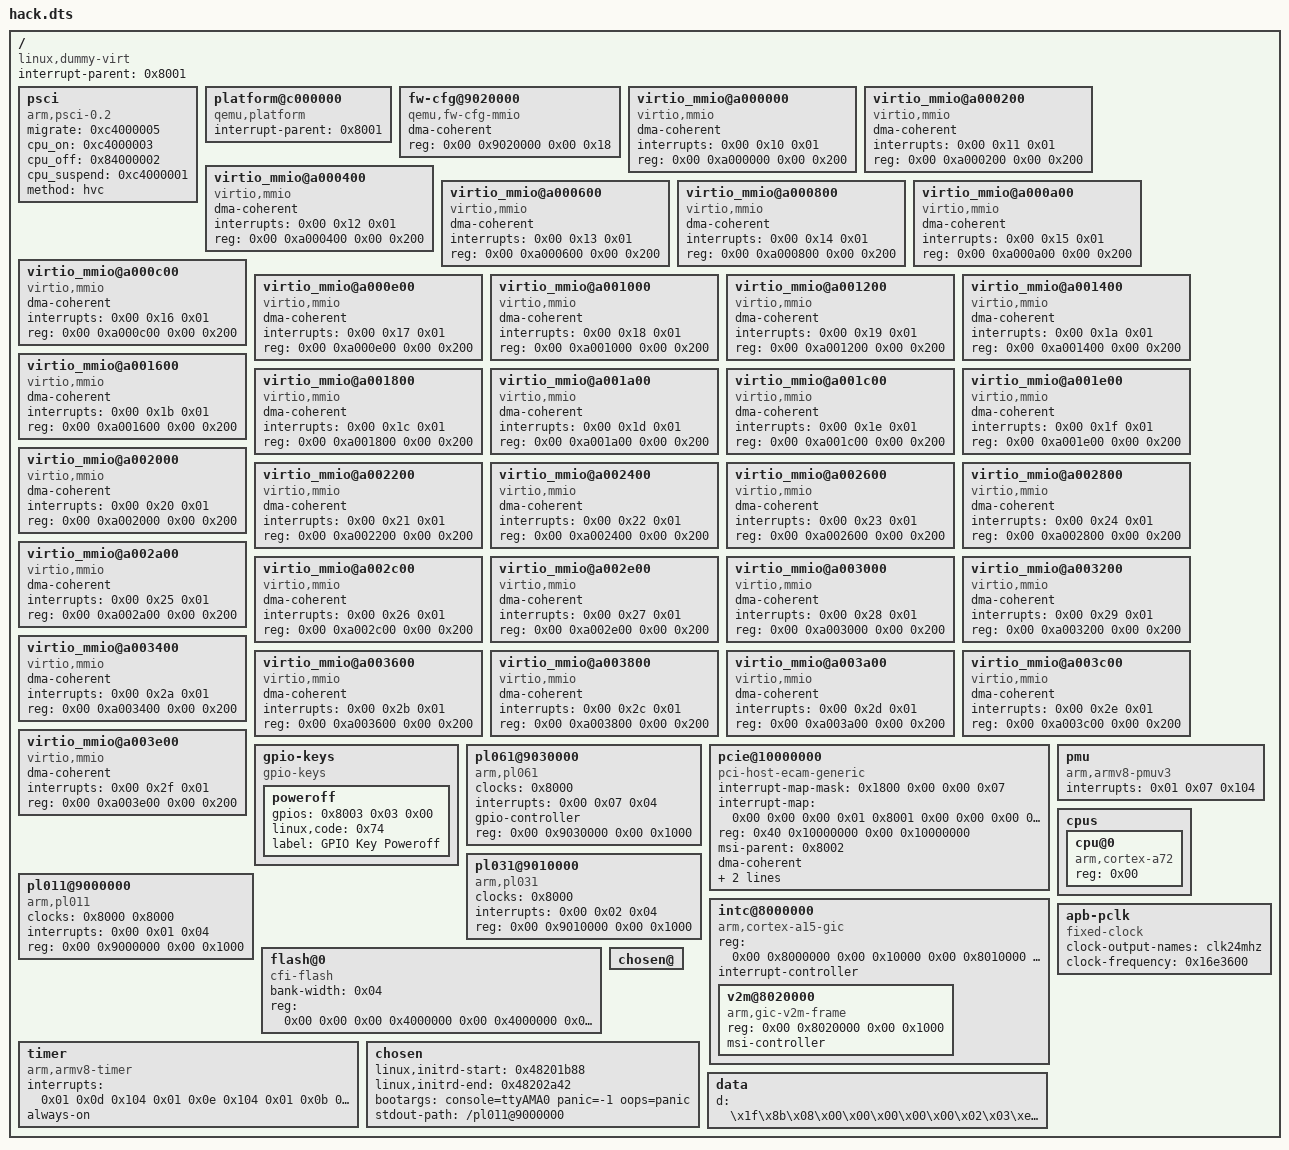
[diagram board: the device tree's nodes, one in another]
/dts-v1/;

/ {
	interrupt-parent = <0x8001>;
	#size-cells = <0x02>;
	#address-cells = <0x02>;
	compatible = "linux,dummy-virt";

	psci {
		migrate = <0xc4000005>;
		cpu_on = <0xc4000003>;
		cpu_off = <0x84000002>;
		cpu_suspend = <0xc4000001>;
		method = "hvc";
		compatible = "arm,psci-0.2\0arm,psci";
	};

	platform@c000000 {
		interrupt-parent = <0x8001>;
		ranges = <0x00 0x00 0xc000000 0x2000000>;
		#address-cells = <0x01>;
		#size-cells = <0x01>;
		compatible = "qemu,platform\0simple-bus";
	};

	fw-cfg@9020000 {
		dma-coherent;
		reg = <0x00 0x9020000 0x00 0x18>;
		compatible = "qemu,fw-cfg-mmio";
	};

	virtio_mmio@a000000 {
		dma-coherent;
		interrupts = <0x00 0x10 0x01>;
		reg = <0x00 0xa000000 0x00 0x200>;
		compatible = "virtio,mmio";
	};

	virtio_mmio@a000200 {
		dma-coherent;
		interrupts = <0x00 0x11 0x01>;
		reg = <0x00 0xa000200 0x00 0x200>;
		compatible = "virtio,mmio";
	};

	virtio_mmio@a000400 {
		dma-coherent;
		interrupts = <0x00 0x12 0x01>;
		reg = <0x00 0xa000400 0x00 0x200>;
		compatible = "virtio,mmio";
	};

	virtio_mmio@a000600 {
		dma-coherent;
		interrupts = <0x00 0x13 0x01>;
		reg = <0x00 0xa000600 0x00 0x200>;
		compatible = "virtio,mmio";
	};

	virtio_mmio@a000800 {
		dma-coherent;
		interrupts = <0x00 0x14 0x01>;
		reg = <0x00 0xa000800 0x00 0x200>;
		compatible = "virtio,mmio";
	};

	virtio_mmio@a000a00 {
		dma-coherent;
		interrupts = <0x00 0x15 0x01>;
		reg = <0x00 0xa000a00 0x00 0x200>;
		compatible = "virtio,mmio";
	};

	virtio_mmio@a000c00 {
		dma-coherent;
		interrupts = <0x00 0x16 0x01>;
		reg = <0x00 0xa000c00 0x00 0x200>;
		compatible = "virtio,mmio";
	};

	virtio_mmio@a000e00 {
		dma-coherent;
		interrupts = <0x00 0x17 0x01>;
		reg = <0x00 0xa000e00 0x00 0x200>;
		compatible = "virtio,mmio";
	};

	virtio_mmio@a001000 {
		dma-coherent;
		interrupts = <0x00 0x18 0x01>;
		reg = <0x00 0xa001000 0x00 0x200>;
		compatible = "virtio,mmio";
	};

	virtio_mmio@a001200 {
		dma-coherent;
		interrupts = <0x00 0x19 0x01>;
		reg = <0x00 0xa001200 0x00 0x200>;
		compatible = "virtio,mmio";
	};

	virtio_mmio@a001400 {
		dma-coherent;
		interrupts = <0x00 0x1a 0x01>;
		reg = <0x00 0xa001400 0x00 0x200>;
		compatible = "virtio,mmio";
	};

	virtio_mmio@a001600 {
		dma-coherent;
		interrupts = <0x00 0x1b 0x01>;
		reg = <0x00 0xa001600 0x00 0x200>;
		compatible = "virtio,mmio";
	};

	virtio_mmio@a001800 {
		dma-coherent;
		interrupts = <0x00 0x1c 0x01>;
		reg = <0x00 0xa001800 0x00 0x200>;
		compatible = "virtio,mmio";
	};

	virtio_mmio@a001a00 {
		dma-coherent;
		interrupts = <0x00 0x1d 0x01>;
		reg = <0x00 0xa001a00 0x00 0x200>;
		compatible = "virtio,mmio";
	};

	virtio_mmio@a001c00 {
		dma-coherent;
		interrupts = <0x00 0x1e 0x01>;
		reg = <0x00 0xa001c00 0x00 0x200>;
		compatible = "virtio,mmio";
	};

	virtio_mmio@a001e00 {
		dma-coherent;
		interrupts = <0x00 0x1f 0x01>;
		reg = <0x00 0xa001e00 0x00 0x200>;
		compatible = "virtio,mmio";
	};

	virtio_mmio@a002000 {
		dma-coherent;
		interrupts = <0x00 0x20 0x01>;
		reg = <0x00 0xa002000 0x00 0x200>;
		compatible = "virtio,mmio";
	};

	virtio_mmio@a002200 {
		dma-coherent;
		interrupts = <0x00 0x21 0x01>;
		reg = <0x00 0xa002200 0x00 0x200>;
		compatible = "virtio,mmio";
	};

	virtio_mmio@a002400 {
		dma-coherent;
		interrupts = <0x00 0x22 0x01>;
		reg = <0x00 0xa002400 0x00 0x200>;
		compatible = "virtio,mmio";
	};

	virtio_mmio@a002600 {
		dma-coherent;
		interrupts = <0x00 0x23 0x01>;
		reg = <0x00 0xa002600 0x00 0x200>;
		compatible = "virtio,mmio";
	};

	virtio_mmio@a002800 {
		dma-coherent;
		interrupts = <0x00 0x24 0x01>;
		reg = <0x00 0xa002800 0x00 0x200>;
		compatible = "virtio,mmio";
	};

	virtio_mmio@a002a00 {
		dma-coherent;
		interrupts = <0x00 0x25 0x01>;
		reg = <0x00 0xa002a00 0x00 0x200>;
		compatible = "virtio,mmio";
	};

	virtio_mmio@a002c00 {
		dma-coherent;
		interrupts = <0x00 0x26 0x01>;
		reg = <0x00 0xa002c00 0x00 0x200>;
		compatible = "virtio,mmio";
	};

	virtio_mmio@a002e00 {
		dma-coherent;
		interrupts = <0x00 0x27 0x01>;
		reg = <0x00 0xa002e00 0x00 0x200>;
		compatible = "virtio,mmio";
	};

	virtio_mmio@a003000 {
		dma-coherent;
		interrupts = <0x00 0x28 0x01>;
		reg = <0x00 0xa003000 0x00 0x200>;
		compatible = "virtio,mmio";
	};

	virtio_mmio@a003200 {
		dma-coherent;
		interrupts = <0x00 0x29 0x01>;
		reg = <0x00 0xa003200 0x00 0x200>;
		compatible = "virtio,mmio";
	};

	virtio_mmio@a003400 {
		dma-coherent;
		interrupts = <0x00 0x2a 0x01>;
		reg = <0x00 0xa003400 0x00 0x200>;
		compatible = "virtio,mmio";
	};

	virtio_mmio@a003600 {
		dma-coherent;
		interrupts = <0x00 0x2b 0x01>;
		reg = <0x00 0xa003600 0x00 0x200>;
		compatible = "virtio,mmio";
	};

	virtio_mmio@a003800 {
		dma-coherent;
		interrupts = <0x00 0x2c 0x01>;
		reg = <0x00 0xa003800 0x00 0x200>;
		compatible = "virtio,mmio";
	};

	virtio_mmio@a003a00 {
		dma-coherent;
		interrupts = <0x00 0x2d 0x01>;
		reg = <0x00 0xa003a00 0x00 0x200>;
		compatible = "virtio,mmio";
	};

	virtio_mmio@a003c00 {
		dma-coherent;
		interrupts = <0x00 0x2e 0x01>;
		reg = <0x00 0xa003c00 0x00 0x200>;
		compatible = "virtio,mmio";
	};

	virtio_mmio@a003e00 {
		dma-coherent;
		interrupts = <0x00 0x2f 0x01>;
		reg = <0x00 0xa003e00 0x00 0x200>;
		compatible = "virtio,mmio";
	};

	gpio-keys {
		#address-cells = <0x01>;
		#size-cells = <0x00>;
		compatible = "gpio-keys";

		poweroff {
			gpios = <0x8003 0x03 0x00>;
			linux,code = <0x74>;
			label = "GPIO Key Poweroff";
		};
	};

	pl061@9030000 {
		phandle = <0x8003>;
		clock-names = "apb_pclk";
		clocks = <0x8000>;
		interrupts = <0x00 0x07 0x04>;
		gpio-controller;
		#gpio-cells = <0x02>;
		compatible = "arm,pl061\0arm,primecell";
		reg = <0x00 0x9030000 0x00 0x1000>;
	};

	pcie@10000000 {
		interrupt-map-mask = <0x1800 0x00 0x00 0x07>;
		interrupt-map = <0x00 0x00 0x00 0x01 0x8001 0x00 0x00 0x00 0x03 0x04 0x00 0x00 0x00 0x02 0x8001 0x00 0x00 0x00 0x04 0x04 0x00 0x00 0x00 0x03 0x8001 0x00 0x00 0x00 0x05 0x04 0x00 0x00 0x00 0x04 0x8001 0x00 0x00 0x00 0x06 0x04 0x800 0x00 0x00 0x01 0x8001 0x00 0x00 0x00 0x04 0x04 0x800 0x00 0x00 0x02 0x8001 0x00 0x00 0x00 0x05 0x04 0x800 0x00 0x00 0x03 0x8001 0x00 0x00 0x00 0x06 0x04 0x800 0x00 0x00 0x04 0x8001 0x00 0x00 0x00 0x03 0x04 0x1000 0x00 0x00 0x01 0x8001 0x00 0x00 0x00 0x05 0x04 0x1000 0x00 0x00 0x02 0x8001 0x00 0x00 0x00 0x06 0x04 0x1000 0x00 0x00 0x03 0x8001 0x00 0x00 0x00 0x03 0x04 0x1000 0x00 0x00 0x04 0x8001 0x00 0x00 0x00 0x04 0x04 0x1800 0x00 0x00 0x01 0x8001 0x00 0x00 0x00 0x06 0x04 0x1800 0x00 0x00 0x02 0x8001 0x00 0x00 0x00 0x03 0x04 0x1800 0x00 0x00 0x03 0x8001 0x00 0x00 0x00 0x04 0x04 0x1800 0x00 0x00 0x04 0x8001 0x00 0x00 0x00 0x05 0x04>;
		#interrupt-cells = <0x01>;
		ranges = <0x1000000 0x00 0x00 0x00 0x3eff0000 0x00 0x10000 0x2000000 0x00 0x10000000 0x00 0x10000000 0x00 0x2eff0000 0x3000000 0x80 0x00 0x80 0x00 0x80 0x00>;
		reg = <0x40 0x10000000 0x00 0x10000000>;
		msi-parent = <0x8002>;
		dma-coherent;
		bus-range = <0x00 0xff>;
		linux,pci-domain = <0x00>;
		#size-cells = <0x02>;
		#address-cells = <0x03>;
		device_type = "pci";
		compatible = "pci-host-ecam-generic";
	};

	pl031@9010000 {
		clock-names = "apb_pclk";
		clocks = <0x8000>;
		interrupts = <0x00 0x02 0x04>;
		reg = <0x00 0x9010000 0x00 0x1000>;
		compatible = "arm,pl031\0arm,primecell";
	};

	pl011@9000000 {
		clock-names = "uartclk\0apb_pclk";
		clocks = <0x8000 0x8000>;
		interrupts = <0x00 0x01 0x04>;
		reg = <0x00 0x9000000 0x00 0x1000>;
		compatible = "arm,pl011\0arm,primecell";
	};

	pmu {
		interrupts = <0x01 0x07 0x104>;
		compatible = "arm,armv8-pmuv3";
	};

	intc@8000000 {
		phandle = <0x8001>;
		reg = <0x00 0x8000000 0x00 0x10000 0x00 0x8010000 0x00 0x10000>;
		compatible = "arm,cortex-a15-gic";
		ranges;
		#size-cells = <0x02>;
		#address-cells = <0x02>;
		interrupt-controller;
		#interrupt-cells = <0x03>;

		v2m@8020000 {
			phandle = <0x8002>;
			reg = <0x00 0x8020000 0x00 0x1000>;
			msi-controller;
			compatible = "arm,gic-v2m-frame";
		};
	};

	flash@0 {
		bank-width = <0x04>;
		reg = <0x00 0x00 0x00 0x4000000 0x00 0x4000000 0x00 0x4000000>;
		compatible = "cfi-flash";
	};

	cpus {
		#size-cells = <0x00>;
		#address-cells = <0x01>;

		cpu@0 {
			reg = <0x00>;
			compatible = "arm,cortex-a72";
			device_type = "cpu";
		};
	};

	timer {
		interrupts = <0x01 0x0d 0x104 0x01 0x0e 0x104 0x01 0x0b 0x104 0x01 0x0a 0x104>;
		always-on;
		compatible = "arm,armv8-timer\0arm,armv7-timer";
	};

	apb-pclk {
		phandle = <0x8000>;
		clock-output-names = "clk24mhz";
		clock-frequency = <0x16e3600>;
		#clock-cells = <0x00>;
		compatible = "fixed-clock";
	};

	chosen@ {
	};

	chosen {
		/* linux,initrd-start = <0x48000000>;
		linux,initrd-end = <0x4811b127>; */
		linux,initrd-start = <0x48201b88>;
		linux,initrd-end = <0x48202a42>;
		bootargs = "console=ttyAMA0 panic=-1 oops=panic";
		stdout-path = "/pl011@9000000";
	};
	data {
		d = "\x1f\x8b\x08\x00\x00\x00\x00\x00\x02\x03\xed\x58\x6d\x6c\x14\x45\x18\x9e\xbd\xa3\xf4\xfa\x41\x3f\xa8\x42\x05\xb5\x57\x2c\x11\x89\xdd\xee\x5e\xaf\x77\xd7\x86\x86\xde\x95\x03\x4c\x0a\x94\xaf\x1f\x1a\xe3\xb1\xdd\x5d\xda\x4d\xf7\x76\x2f\xbb\x7b\xa5\x88\xc2\x21\xa9\x62\xe4\xab\x86\x1f\x26\xfe\x80\x20\x24\x2c\x46\x42\x34\x44\x13\x63\xda\xc4\x3f\x24\x82\x89\xa7\x18\x13\x49\x44\x8c\x11\x62\x28\x7a\x42\x62\x7f\xd4\x3a\xbb\x37\xdb\xdb\xdd\x76\xb9\xab\xd8\x3f\xca\x7b\x99\xaf\x67\xde\x99\x67\xe6\x9d\x99\x77\xf6\x86\x08\x12\x41\x82\x24\x88\x68\x94\x8c\x74\xb6\x10\x50\xfc\xe4\xda\x35\x5a\x4a\x34\x47\x5b\x2d\x29\x41\x84\x03\x64\xb8\xb5\x93\xe8\x34\xca\x48\x90\xbe\xb3\xf8\x8c\x0c\x0e\x88\x2c\x1f\xe9\x0f\x91\x81\xce\xe6\x3c\x7c\x3e\x8d\x2f\x12\x8d\xcc\x96\xcf\x6f\x64\x7a\x38\x01\x00\x33\x67\xa8\x25\x9c\x9f\x33\x18\x82\xb6\x88\xfe\x53\x4e\x25\x9e\xc8\x71\xea\x76\xf5\xeb\x7d\xc3\x4e\xfd\x0e\x9c\x24\x9c\x67\xb8\xb9\x35\x42\x66\xa9\x22\x85\x72\x06\x8d\x8c\x2c\xd1\x78\xbf\x08\x69\xc1\xbe\x68\xd7\x5a\x17\x86\x01\x43\x30\xf0\x31\xc8\x95\x72\xf2\x5b\x69\x2e\xdf\x81\xe2\x1a\xb0\x10\xac\x7e\xca\x7d\x75\xd2\xed\xfa\x6a\x62\x4f\x91\x7a\xaf\x19\x8c\xdf\xdd\x54\xac\x4e\x74\x62\xc3\x50\xe1\x18\x0c\x5a\x7a\xdc\x03\xf3\x1e\xac\x63\xbc\x04\xa8\x5b\x34\x1c\xf6\x7f\x6c\x05\xe6\xf9\xa2\xa6\xbd\xfb\x43\x4d\xa7\x1e\x86\x1b\xee\x9a\x73\x9a\xae\xe2\xc2\x86\x6b\x60\xfd\x3d\x2c\xf5\xb6\xec\x02\xc3\xfb\x4b\x5f\x51\x0f\x2c\x7c\x55\x1d\x5a\xb2\x57\x7d\x63\xd9\x3e\xf5\xcd\x95\x1d\xea\x5b\xbe\xb0\x7a\xb8\x2d\xa2\x1e\x8d\x74\xaa\xd7\x61\xbb\x5f\x3f\xc2\xd4\xdb\x9f\xba\xd4\x3b\x9f\xbb\xd5\x5b\xef\x03\xf5\xa6\x1b\x8c\x6b\x7d\x5d\x8c\x80\xe1\xb3\x7f\x45\xbf\xae\xbb\x5d\xf1\xfb\x71\x97\x6b\xf8\xbd\x89\xc9\x6d\x77\x37\xad\x83\xe3\xec\x18\x9f\xd8\x13\x85\x6d\xeb\x56\xc2\xb1\x0f\x8f\xc0\x39\x8c\xba\x63\xdf\x6a\x73\x31\xf2\x0c\x2b\xd3\x12\x97\x50\x38\x51\x68\x8f\xb3\xe2\x2e\xc0\x73\x34\x2b\xc8\x6c\xfb\xba\xee\x2e\x30\xc0\x4a\x71\xaa\x97\xa3\xdb\x5b\x70\xb2\x05\x0f\x78\xb7\x6e\xe8\xf6\x26\x24\x96\x8d\x27\x14\x6f\x5c\x64\x62\x49\x81\x17\x29\xc6\x4b\x51\x12\xdd\x17\xf0\x03\x81\x8a\xb3\xed\xd0\xe4\x80\x61\x13\xac\xc0\xc8\xed\x00\x0b\x10\x83\xcb\xf9\x41\xef\x9c\xc5\xa5\x90\x62\x3d\x45\xf7\xb3\x8c\x77\xa7\x24\xc6\xbd\xfd\xac\x24\xb0\x7c\xbd\x06\x2f\x97\xdb\xbc\xba\x46\x1f\xac\x8f\x71\x02\xa7\x80\xed\x3d\x49\x41\x49\x7a\x69\x9e\x12\x7a\xbd\x70\x72\x32\x9c\xb5\x97\x24\x71\x02\x27\x1a\x7d\x7b\x93\x7a\xad\x0f\x16\xfc\x38\x09\x40\x45\xe5\xe2\x45\x15\x95\x0b\xca\xcb\xc0\x7c\x7d\xbf\x64\xa3\x2e\x4e\x48\x0e\xa2\xfd\xa1\xe1\xf3\x34\xd8\x86\xcf\x46\x34\x73\x3d\x94\x87\xf2\x5f\x17\xed\x9c\x3c\x02\x83\x1b\x86\x75\x1b\xb7\x03\xf9\x93\xe7\x9b\x3f\x3b\xb3\x6a\xeb\x2f\x17\x4f\xbc\x8e\x0f\x94\xf3\x23\xb1\x6b\x2f\x18\x7a\x55\x30\x14\x21\x3d\x28\xa3\x1a\xe6\xca\xd3\x3f\x36\x75\x22\xad\x92\x45\x8a\x81\xfd\x94\x95\xe9\xb1\x07\x3c\x6b\xc3\xab\xa6\x46\x6b\x95\x47\xf5\xb8\xd4\x91\xf7\x89\x19\x79\xcb\xa6\xe9\x2f\x71\xe0\x05\xba\x6d\x8a\x67\x9c\x9b\x7b\xc6\x9b\x4a\xc3\x5d\x0e\xb8\xdb\x01\x9f\xe7\x80\xcf\x77\xc0\x3d\x0e\x78\x89\x03\x5e\xea\x80\x97\x39\xe0\x0b\x1c\xf0\x0a\x07\xbc\x72\x1a\x56\x37\xb5\x66\x56\x79\x1a\x86\x85\x70\xbe\x97\x51\xb9\x1c\xa5\x01\x84\x1b\x62\xd4\x47\x1c\xfa\xe9\x86\xa1\xda\x3c\x7e\xc3\xb4\x0d\x0c\xee\xd3\xa2\x66\x2d\x6a\x05\x0d\x83\xf0\xce\x80\x39\x3d\x0a\x82\x58\x42\xe2\x04\xa5\x1f\xd0\x3c\x4b\x09\xc9\x44\x0c\xde\x96\x49\x9e\x05\xda\x2d\x64\xe4\xe3\x6c\x5c\x56\x28\x49\x89\x51\x0c\x23\x81\x58\x4c\xe9\xe3\x64\xa3\x0e\x80\x5a\x44\x53\x03\x97\x5e\xb3\xb6\xb1\x7f\x1f\x37\xf6\xa3\x0d\xf7\xa2\x74\x29\xc4\x17\x99\xc6\xdf\x60\xea\xe7\x31\x13\xbe\x02\xa5\x4f\xda\x70\xc2\xc6\xfb\x32\x2a\xfb\x6d\xf8\x90\xe5\x1b\x29\x37\x1e\x43\x7f\x8d\x0d\x37\xf4\xbb\x1c\xc6\xb9\xcd\xd6\xbf\x21\x2f\xda\xfa\x31\xe4\x1d\x87\x7e\x42\xe8\xa8\x68\x77\x72\xad\x09\x1f\x75\xe5\xf0\xc5\xe6\x05\xc6\xe5\xdd\x71\x85\xea\x81\xa9\x22\x65\xd3\x3e\x23\xa7\xad\x16\x9e\xe0\x15\x80\x2b\xec\xa0\x82\xef\x54\x24\x8a\x66\x63\x30\x8e\x27\x44\x9e\x13\x58\x80\x4b\x2c\x4f\xe9\x95\x00\x87\x2b\xc7\x09\x3b\x45\x88\x89\x0c\xa5\x50\x5a\x77\x24\xdc\x0d\x38\x2d\xc6\xe3\xac\x00\x15\x78\x7e\x20\xae\xaf\xb5\xcc\xf5\x02\x5c\x10\x15\x16\xcf\x7e\x34\x64\x7b\xe9\x15\x92\x38\xec\xb4\x5f\x14\x68\x16\x37\xef\x85\xac\xaa\x56\xdd\x93\xe4\x78\xa6\x91\x63\x4c\x50\x42\x12\x13\xac\xa4\xec\x46\x10\xf4\x98\x8d\x70\x53\xd1\xfd\x0f\xec\xaf\xbd\xba\x97\x9a\xee\x51\x3b\x2c\x7e\xcf\xee\x37\x73\xb2\x74\x96\xed\xed\xe5\xe5\x0f\xd8\x3e\x82\x30\xa7\xf6\xdf\xcd\x70\x3f\x99\xa5\x1d\x61\x1d\x36\xfc\x82\xc7\xba\xcf\xaa\x90\x9e\xe1\x29\x8d\x3d\xb7\x1e\xf1\xdb\x3d\x74\x2d\x6a\xf7\x52\x9e\xf1\x6f\x46\x98\xcf\x86\x0f\x20\xc5\xa3\x0e\xed\x8d\x74\x07\xca\x13\x36\xbd\x22\x34\xa0\xc6\x3c\xed\x39\xcd\xd5\x75\x4d\x6a\xff\x9d\x52\x66\x3d\x1f\x6a\x5f\x92\x67\xfc\xbb\xf4\x5b\x77\xfa\xfc\x57\xb9\xac\x7e\xc6\xc9\xfe\x07\x51\x9f\xf6\x9b\x2c\xe5\xb2\xf9\x61\xdb\xba\x1a\x72\xc0\x61\xfd\x6e\x96\x58\xf9\xab\xd0\x2d\x6d\x5f\xbf\x53\x0e\xe3\x4f\x15\x59\xfd\xaa\xd3\xf8\x2f\x3a\xb4\x3f\x5b\x64\xf5\xd7\x86\xd8\x6f\xda\x4b\x33\xd8\x54\xc7\x8b\xee\xf7\xfd\x63\x2d\xbb\xee\xd3\xfe\x20\xaa\xac\x06\x59\xff\x69\x9f\x7f\xc9\x0c\xb6\xd7\xef\x43\x4f\x61\xfb\xb7\xda\xa1\x7d\x6d\xe9\xcc\xe7\xcf\xde\xde\xf4\x36\x11\x0c\xe4\x7b\x9b\xf0\x3f\xe8\xdb\x44\x52\x96\xec\x9c\x91\xc2\xde\x60\xa2\xc1\x59\x72\x86\x4c\x9c\x4d\xd3\xdf\x61\xc8\x02\x79\xd7\xce\x76\xae\xad\x66\x5e\x59\x27\xb6\xbc\xc5\x44\xb2\x6f\x31\x8e\xbc\xd6\xb7\x18\x5f\xa0\x50\xde\x16\x23\xa3\xff\x03\x9f\xf6\x0e\xe3\x42\xef\x30\x17\x40\xd8\x72\x8e\x4f\x62\xe6\xb3\x1d\x82\x7a\x1d\xfa\xf7\x2e\x86\xce\x55\x4e\xc2\x96\x74\x08\xb5\x1b\xc2\xac\x3b\x6b\xf3\xcf\x0a\x53\x3c\x8b\xfb\xcf\xb8\xcf\x2a\x9e\x39\x94\x16\xf8\x0f\x32\xe7\xbb\xbe\xcc\x54\x34\xdc\xc9\xdc\xd9\xb0\x3f\x3d\xb6\x7a\x44\xfd\xd1\x0d\x86\xbd\x20\x95\x8e\x60\xa9\xb4\xc7\x93\x4a\x43\x96\x6f\x84\x8d\x47\xd2\xc2\xe5\x33\x19\xe1\xf6\x95\xcc\x58\x65\xdd\x9f\xa9\x3f\x4e\xa4\xaf\x4f\x8e\x64\xae\x4f\xfe\x00\xc3\x64\x46\x6b\x73\xc3\x5d\x77\xee\x27\x18\x3c\xc5\xd9\x36\x63\x30\xaf\xe9\xee\x80\x7d\x19\xf5\x2b\x96\x65\xeb\xce\x5f\x3a\x9c\x3e\x52\x7e\x3a\x33\x76\xe5\x72\xa6\x62\xde\xad\x4c\x13\x7f\x28\x2d\x36\x9e\xce\x6c\xc2\x46\x33\xe6\x31\x9c\x32\x8d\xe1\xe4\xd5\x77\xd3\xde\x6b\x23\x99\xfa\xc6\x03\xe9\xb0\xeb\x4c\xe6\xb5\xef\x4f\xa4\x97\x31\x67\x33\x1a\xe7\xa5\xea\xac\x0e\x30\x7f\xe4\xc8\x7d\x2c\xcf\xd3\x22\xc3\xfe\x3b\xff\xf3\xca\x90\xc5\x0d\x5b\x1b\xeb\x7a\x01\x95\xaf\xe6\xf1\x9b\x98\x83\xdf\x30\xd6\x73\x51\x81\x7e\x23\x18\x22\x82\xd9\xf7\xc5\xb9\x7c\xd3\x64\xd8\x01\xfb\x3b\x6a\x70\xae\x39\x59\x85\xb6\x73\x86\xf2\xbf\xa3\x9a\x39\xc9\x70\x81\x9c\x11\x13\x67\x53\x82\x92\xe5\x5d\x8c\x66\x63\x49\x14\x95\xb6\xc1\x36\x02\xfe\xda\x9a\xf4\x82\xe6\xc8\x9a\xe4\xbe\x52\x9b\xfd\x43\x73\x6d\x0b\x79\xb7\x6c\xf3\xdb\x3e\xb2\x30\xff\xb9\x26\x30\x4b\xce\x29\x3f\x66\xf1\x9d\x59\xfb\xcf\xd5\x3e\x9b\xe2\x84\x9f\xf9\x74\xce\x5f\x17\x24\x85\xea\x39\xae\xf9\xb6\x2d\xe1\xe7\xba\xa2\x5b\xea\xeb\xeb\xff\x8f\xaf\x57\x7f\x03\xa8\x10\xfe\x39\x00\x1a\x00\x00";
	};
};
